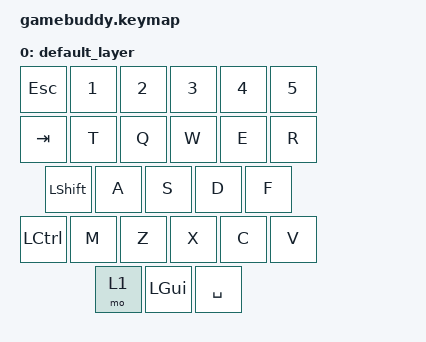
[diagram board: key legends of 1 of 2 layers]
/*
 * Copyright (c) 2020 The ZMK Contributors
 *
 * SPDX-License-Identifier: MIT
 */

#include <behaviors.dtsi>
#include <dt-bindings/zmk/keys.h>
#include <dt-bindings/zmk/bt.h>
#include <dt-bindings/zmk/modifiers.h>

/ {
    keymap {
        compatible = "zmk,keymap";

        default_layer {

// -----------------------
// | ESC |  1  |  2  |  3  |  4  |  5 |
// | TAB  |  T  |  Q  |  W  |  E  |  R  | 
// | SHIFT |  A  |  S  |  D  |  F  |
// |  CTL  |  M  |  Z  |  X  |  C  |  V  |
// |  ALT  |  WIN  |     SPACE              
// ---------------------------------

			bindings = <
	&kp ESC	&kp N1 &kp N2 &kp N3 &kp N4 &kp N5
	&kp TAB &kp T &kp Q  &kp W  &kp E  &kp R
	&kp LSHFT  &kp A  &kp S  &kp D  &kp F  
	&kp LCTRL  &kp M &kp Z  &kp X  &kp C  &kp V
	&mo 1 &kp LGUI &kp SPACE
			>;
		};

		fn_layer {
			bindings = <
	&reset &kp K_SLEEP &bt BT_SEL 0 &bt BT_NXT &bt BT_CLR &kp N5
	&none &none &none &kp C_VOLUME_UP  &none &none
	&none &none  &kp C_VOLUME_DOWN  &none &none
	&none  &kp C_MUTE &none &none &none &none
			>;
		};
	};
};
